# f28003x_test_error_regs register map
Vendor: Texas Instruments
Peripheral module from a debugger description file (folder C2000).
Address unit: 16 bits
Registers are 32-bit, read-only, no defined reset value unless marked. A register's access mark holds for its fields unless they carry their own. Offsets are as the file gives them; lines under a group give offsets from that group; [hi:lo] are bit positions; {n}, {i} and the like mark numbered series; 'fields as' and 'values as' point back to an identical list; <NAME> marks a mode.

## TEST_ERROR_REGS — TEST ERROR Registers
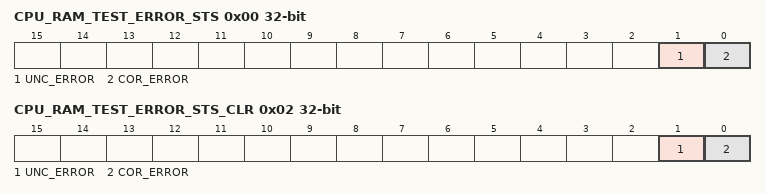
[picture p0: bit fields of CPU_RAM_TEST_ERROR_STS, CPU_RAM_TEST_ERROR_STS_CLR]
0x00 CPU_RAM_TEST_ERROR_STS — Ram Test: Error Status Register
  [1] UNC_ERROR — UNC_ERROR flag
  [0] COR_ERROR — COR_ERROR flag
0x02 CPU_RAM_TEST_ERROR_STS_CLR rw — Ram Test: Error Status Clear Register
  [1] UNC_ERROR — UNC_ERROR flag clear bit
  [0] COR_ERROR — COR_ERROR flag clear bit
0x04 CPU_RAM_TEST_ERROR_ADDR — Ram Test: Error address register
  [31:0] ADDR — Address which generated the error in the RAM/ROM TEST modes.
